AUTOSAR XML (schema 00046)
package /Runnable_Lab1
  sender receiver interface SR1_Throttle
    data Throttle_CMD: type=uint32
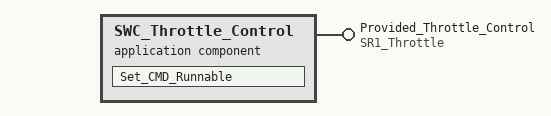
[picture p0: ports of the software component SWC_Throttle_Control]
  application sw component type SWC_Throttle_Control
    provide port Provided_Throttle_Control: provided-interface=SR1_Throttle
    behavior Throttle_Internal_Beh
      runnable Set_CMD_Runnable: symbol=SeT_CMD
        data-write-access:
          access Throttle_Data: accessed-variable=Provided_Throttle_Control.Throttle_CMD
